VERSION "created by canmatrix"

NS_ :

BS_:

BU_: RT EPS_C

BO_ 361 VCU_SES_REQ: 8 RT
 SG_ SES_AlignEnable : 0|1@1+ (1,0) [0|1] "" Vector__XXX
 SG_ SES_CtrlEnable : 1|1@1+ (1,0) [0|1] "" Vector__XXX
 SG_ SES_TgtStrAngle : 16|16@1- (0.1000000000000000055511151231257827021181583404541015625,-3000) [-700|700] "deg" Vector__XXX
 SG_ SES_TgtStrAngleSpd : 32|16@1+ (1,0) [125|525] "deg/s" Vector__XXX
 SG_ SES_RollCntEnable : 40|1@1+ (1,0) [0|1] "" Vector__XXX
 SG_ SES_ChecksumEnable : 41|1@1+ (1,0) [0|1] "" Vector__XXX
 SG_ SES_RollCnt : 44|4@1+ (1,0) [0|15] "" Vector__XXX
 SG_ SES_VehSpd : 48|8@1+ (1,0) [0|255] "km/h" Vector__XXX
 SG_ SES_Checksum : 56|8@1+ (1,0) [0|255] "" Vector__XXX

BO_ 513 SES_STATUS: 8 EPS_C
 SG_ SES_AngleStatus : 0|1@1+ (1,0) [0|1] "" Vector__XXX
 SG_ SES_CtrlModeStatus : 1|2@1+ (1,0) [0|3] "" Vector__XXX
 SG_ SES_ErrorStatus : 6|2@1+ (1,0) [0|3] "enum" Vector__XXX
 SG_ SES_StrAngle : 16|16@1+ (0.1000000000000000055511151231257827021181583404541015625,-3000) [-700|700] "deg" Vector__XXX
 SG_ SES_TgtStrAngleSpd_FB : 32|16@1- (0.5,0) [0|1480] "deg/s" Vector__XXX
 SG_ SES_SteeringTorq : 40|8@1+ (0.1000000000000000055511151231257827021181583404541015625,-12.0999999999999996447286321199499070644378662109375) [-12|12] "Nm" Vector__XXX
 SG_ SES_RollCntEnStatus : 48|1@1+ (1,0) [0|1] "" Vector__XXX
 SG_ SES_ChecksumEnStatus : 49|1@1+ (1,0) [0|1] "" Vector__XXX
 SG_ SES_RollCntStatus : 52|4@1+ (1,0) [0|15] "" Vector__XXX
 SG_ SES_ChecksumStatus : 56|8@1+ (1,0) [0|255] "" Vector__XXX

BO_ 514 SES_ErrInfo: 8 EPS_C
 SG_ SES_ECUUnderVolt : 0|1@1+ (1,0) [0|1] "" Vector__XXX
 SG_ SES_ECUOverVolt : 1|1@1+ (1,0) [0|1] "" Vector__XXX
 SG_ SES_CanComErr : 2|1@1+ (1,0) [0|1] "" Vector__XXX
 SG_ SES_ECUTempErr : 3|1@1+ (1,0) [0|1] "" Vector__XXX
 SG_ SES_DomainSC : 4|1@1+ (1,0) [0|1] "" Vector__XXX
 SG_ SES_DomainV : 5|1@1+ (1,0) [0|1] "" Vector__XXX
 SG_ SES_DomainT : 6|1@1+ (1,0) [0|1] "" Vector__XXX
 SG_ SES_TempSensor : 7|1@1+ (1,0) [0|1] "" Vector__XXX
 SG_ SES_AngleP_OC : 8|1@1+ (1,0) [0|1] "" Vector__XXX
 SG_ SES_AngleP_AF : 9|1@1+ (1,0) [0|1] "" Vector__XXX
 SG_ SES_AngleS_OC : 10|1@1+ (1,0) [0|1] "" Vector__XXX
 SG_ SES_AngleS_AF : 11|1@1+ (1,0) [0|1] "" Vector__XXX
 SG_ SES_SensorPow : 12|1@1+ (1,0) [0|1] "" Vector__XXX
 SG_ SES_Alignment : 13|1@1+ (1,0) [0|1] "" Vector__XXX
 SG_ SES_OverAngle : 14|1@1+ (1,0) [0|1] "" Vector__XXX
 SG_ SES_StrMtrStall : 15|1@1+ (1,0) [0|1] "" Vector__XXX
 SG_ SES_MtrCurtFault : 16|1@1+ (1,0) [0|1] "" Vector__XXX
 SG_ SES_SensorCL : 17|1@1+ (1,0) [0|1] "" Vector__XXX
 SG_ SES_TorqT1_OC : 18|1@1+ (1,0) [0|1] "" Vector__XXX
 SG_ SES_TorqT1_AF : 19|1@1+ (1,0) [0|1] "" Vector__XXX
 SG_ SES_TorqT2_OC : 20|1@1+ (1,0) [0|1] "" Vector__XXX
 SG_ SES_TorqT2_AF : 21|1@1+ (1,0) [0|1] "" Vector__XXX
 SG_ SES_SentAngle : 22|1@1+ (1,0) [0|1] "" Vector__XXX
 SG_ SES_StrMtrIdling : 23|1@1+ (1,0) [0|1] "" Vector__XXX
 SG_ SES_EPROM : 24|1@1+ (1,0) [0|1] "" Vector__XXX
 SG_ SES_VehSpdSnapshot : 56|8@1+ (1,0) [0|255] "km/h" Vector__XXX

BO_ 515 SES_Version: 8 EPS_C
 SG_ SES_SW_Version : 0|8@1+ (0.01000000000000000020816681711721685132943093776702880859375,0) [0|2.54999999999999982236431605997495353221893310546875] "" Vector__XXX
 SG_ SES_HW_Version : 8|8@1+ (0.1000000000000000055511151231257827021181583404541015625,0) [0|25.5] "" Vector__XXX

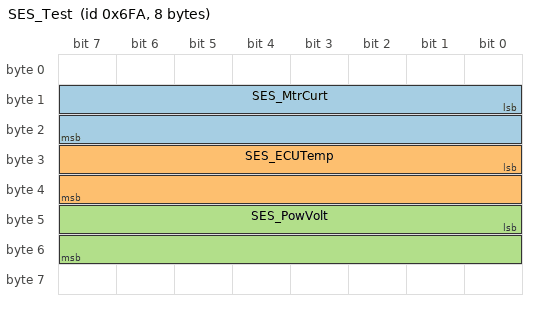
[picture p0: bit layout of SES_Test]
BO_ 1786 SES_Test: 8 EPS_C
 SG_ SES_MtrCurt : 8|16@1- (0.0078125,0) [0|60] "A" Vector__XXX
 SG_ SES_ECUTemp : 24|16@1+ (0.5,0) [0|255] "degC" Vector__XXX
 SG_ SES_PowVolt : 40|16@1+ (0.00390625,0) [0|18] "V" Vector__XXX

CM_ BO_ 361  "SYNTREE EPS-C command. 50 Hz continuous. Byte 5 overlap: Speed[15:8] shares with security nibble per CSV.";
CM_ BO_ 513  "SYNTREE EPS-C status feedback. 100 Hz. Byte 5 overlap: StrAngleSpd[15:8] / Torq share byte 5 per CSV.";
CM_ BO_ 514  "SYNTREE EPS-C detailed fault flags. 8 L3 faults (redundant sensor loss) -> RT must escalate to ESTOP.";
CM_ BO_ 515  "SYNTREE EPS-C firmware version. Log on boot for compatibility check.";
CM_ BO_ 1786  "SYNTREE EPS-C telemetry. 100 Hz. Bytes 0,7 reserved. Narrower ranges than brake SEB_Test.";

CM_ SG_ 361 SES_AlignEnable "Angle Initial Alignment Enable. 0=disabled, 1=centering.";
CM_ SG_ 361 SES_CtrlEnable "Direction Control Enable. 0=Disabled, 1=Enable (Angle Control).";
CM_ SG_ 361 SES_TgtStrAngle "Target Steering Angle. Negative=left. Offset=-3000 per mfr CSV.";
CM_ SG_ 361 SES_TgtStrAngleSpd "Target Angle Speed. Overlaps security signals at byte 5 per CSV.";
CM_ SG_ 361 SES_RollCntEnable "Life Signal Enable  MUST be 1. Overlaps Speed[15:8].";
CM_ SG_ 361 SES_ChecksumEnable "Checksum Enable  MUST be 1.";
CM_ SG_ 361 SES_RollCnt "Life Signal rolling counter. Increment every frame.";
CM_ SG_ 361 SES_VehSpd "Vehicle speed populated by RT.";
CM_ SG_ 361 SES_Checksum "Checksum = XOR(bytes 0-6) ^ 0xFF.";
CM_ SG_ 513 SES_AngleStatus "Center Finding Status. 0=Finding, 1=Found.";
CM_ SG_ 513 SES_CtrlModeStatus "Control Mode Feedback. 0=Manual, 1=Automatic.";
CM_ SG_ 513 SES_ErrorStatus "Error Status.";
CM_ SG_ 513 SES_StrAngle "Steering Angle. Raw 30000->0deg, 23000->-700deg, 37000->700deg.";
CM_ SG_ 513 SES_TgtStrAngleSpd_FB "Angle Speed feedback. 16-bit signed. Overlaps Torq at byte 5.";
CM_ SG_ 513 SES_SteeringTorq "Steering Torque. Init 0x79 (121 raw = 0 Nm). Overlaps Speed[15:8].";
CM_ SG_ 513 SES_RollCntEnStatus "Life Signal Enable Feedback.";
CM_ SG_ 513 SES_ChecksumEnStatus "Checksum Enable Feedback.";
CM_ SG_ 513 SES_RollCntStatus "Life Signal Feedback  echoes rolling counter.";
CM_ SG_ 513 SES_ChecksumStatus "Checksum Feedback = XOR(bytes 0-6) ^ 0xFF.";
CM_ SG_ 514 SES_ECUUnderVolt "Controller Under Voltage [L2]";
CM_ SG_ 514 SES_ECUOverVolt "Controller Over Voltage [L2]";
CM_ SG_ 514 SES_CanComErr "CAN Communication Fault [L1]";
CM_ SG_ 514 SES_ECUTempErr "Controller Temp Fault [L1]";
CM_ SG_ 514 SES_DomainSC "Domain Drive Short Circuit [L2]";
CM_ SG_ 514 SES_DomainV "Domain Drive Voltage Fault [L2]";
CM_ SG_ 514 SES_DomainT "Domain Drive Temperature Fault [L2]";
CM_ SG_ 514 SES_TempSensor "Temperature Sensor Fault";
CM_ SG_ 514 SES_AngleP_OC "Angle Sensor Pri. Open Circuit [L3]";
CM_ SG_ 514 SES_AngleP_AF "Angle Sensor Pri. Out of Range [L3]";
CM_ SG_ 514 SES_AngleS_OC "Angle Sensor Sec. Open Circuit [L3]";
CM_ SG_ 514 SES_AngleS_AF "Angle Sensor Sec. Out of Range [L3]";
CM_ SG_ 514 SES_SensorPow "Sensor Power Fault [L2]";
CM_ SG_ 514 SES_Alignment "Centering Fault [L1]";
CM_ SG_ 514 SES_OverAngle "Over Angle Fault [L2]";
CM_ SG_ 514 SES_StrMtrStall "Motor Stall Fault [L1]";
CM_ SG_ 514 SES_MtrCurtFault "Motor Current Fault [L2]";
CM_ SG_ 514 SES_SensorCL "Sensor 5V Power Fault [L2]";
CM_ SG_ 514 SES_TorqT1_OC "Torque Sensor T1 Open Circuit [L3]";
CM_ SG_ 514 SES_TorqT1_AF "Torque Sensor T1 Out of Range [L3]";
CM_ SG_ 514 SES_TorqT2_OC "Torque Sensor T2 Open Circuit [L3]";
CM_ SG_ 514 SES_TorqT2_AF "Torque Sensor T2 Out of Range [L3]";
CM_ SG_ 514 SES_SentAngle "Angle Error [L1]";
CM_ SG_ 514 SES_StrMtrIdling "Motor Idling Fault [L2]";
CM_ SG_ 514 SES_EPROM "EEPROM Fault [L2]";
CM_ SG_ 514 SES_VehSpdSnapshot "Vehicle speed at fault snapshot.";
CM_ SG_ 515 SES_SW_Version "Software version (e.g. 0x64 = 1.00)";
CM_ SG_ 515 SES_HW_Version "Hardware version (e.g. 0x0D = 1.3)";
CM_ SG_ 1786 SES_MtrCurt "Motor current. Monitor for mechanical binding / rack damage.";
CM_ SG_ 1786 SES_ECUTemp "ECU temperature. For thermal throttling.";
CM_ SG_ 1786 SES_PowVolt "Supply voltage. 0-18V range.";

CM_ BU_ RT "ESP32-S3, FreeRTOS, realtime kinematics + CAN gateway";
CM_ BU_ EPS_C "SYNTREE EPS-C, steer-by-wire module, preprogrammed CAN IDs";

BA_DEF_ BO_ "GenMsgCycleTime" INT 0 65535;

BA_ "GenMsgCycleTime" BO_ 361 20;
BA_ "GenMsgCycleTime" BO_ 513 10;
BA_ "GenMsgCycleTime" BO_ 514 100;
BA_ "GenMsgCycleTime" BO_ 515 1000;
BA_ "GenMsgCycleTime" BO_ 1786 10;

VAL_ 513 SES_ErrorStatus 0 "Normal" 1 "L1_Warning" 2 "L2_General" 3 "L3_Severe";
